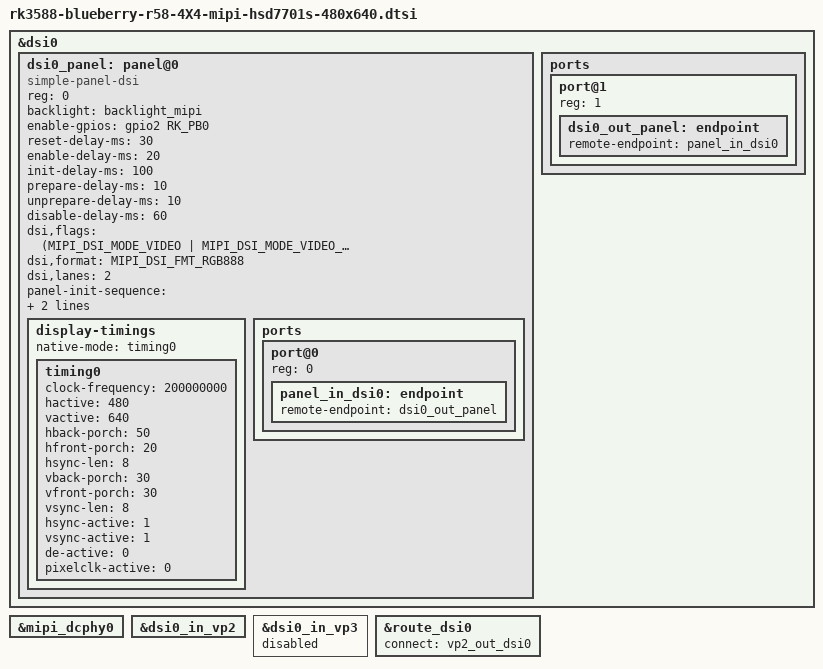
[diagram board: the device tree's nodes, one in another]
// SPDX-License-Identifier: (GPL-2.0+ OR MIT)
/*
 * Copyright (c) 2021 Rockchip Electronics Co., Ltd.
 *
 */

#include "dt-bindings/usb/pd.h"



&dsi0 {
	status = "okay";
	//rockchip,lane-rate = <1000>;
	dsi0_panel: panel@0 {
		status = "okay";
		compatible = "simple-panel-dsi";
		reg = <0>;
		backlight = <&backlight_mipi>;
		//power-supply = <&vcc3v3_mipi_lcd_power>;
		//reset-gpios =  <&gpio3 RK_PC4 GPIO_ACTIVE_LOW>; 
		enable-gpios = <&gpio2 RK_PB0 GPIO_ACTIVE_HIGH>;
		reset-delay-ms = <30>;
		enable-delay-ms = <20>;
		init-delay-ms = <100>;
		prepare-delay-ms = <10>;
		unprepare-delay-ms = <10>;
		disable-delay-ms = <60>;
		dsi,flags = <(MIPI_DSI_MODE_VIDEO | MIPI_DSI_MODE_VIDEO_BURST |
			MIPI_DSI_MODE_LPM | MIPI_DSI_MODE_EOT_PACKET)>;
		dsi,format = <MIPI_DSI_FMT_RGB888>;
		dsi,lanes  = <2>;

		//gc9053v zhengsao
		/*panel-init-sequence = [
			29 00 06 F0 55 AA 52 08 00
			29 00 03 F6 5A 87

			23 00 02 C1 3F
			23 00 02 CD 25
			23 00 02 C9 10

			23 00 02 F8 8A
			23 00 02 AC 45
			23 00 02 A7 47
			23 00 02 A0 DD
			29 00 05 86 99 A3 A3 31
			29 00 05 FA 08 08 00 04
			23 00 02 A3 EE
			29 00 04 FD 28 3C 00

			23 00 02 9A 4A
			23 00 02 9B 22
			29 00 03 82 00 00
			23 00 02 80 64
			23 00 B1 10

			29 00 21 6D 1E 1E 1E 10 0F 0A 09 1E 01 1F 00 07 0D 03 1E 1E 1E 1E 06 0E 08 00 1F 02 1E 11 12 17 18 1E 1E 1E
			29 00 11 64 38 09 02 7F 03 03 38 07 02 81 03 03 7A 7A 7A 7A
			29 00 11 67 38 05 02 83 03 03 38 03 02 85 03 03 7A 7A 7A 7A
			29 00 11 66 72 A7 02 9B 03 03 72 A7 02 9B 03 03 7A 7A 7A 7A
			29 00 11 65 72 A7 02 9B 03 03 72 A7 02 9B 03 03 7A 7A 7A 7A
			29 00 09 60 38 0D 7A 7A 38 0C 7A 7A
			29 00 09 61 B2 9B 7A 7A B2 9C 7A 7A
			29 00 09 62 B2 9C 7A 7A B2 9B 7A 7A
			29 00 09 63 38 0B 7A 7A 38 0A 7A 7A

			23 00 02 6B 07
			29 00 03 7A 13 1A
			29 00 03 7B 13 1A
			29 00 08 69 14 22 14 22 14 22 08

			29 00 35 D1 00 00 00 11 00 5C 00 7F 00 A8 00 D0 00 EE 01 18 01 40 01 84 01 BC 02 14 02 8D 02 8F 02 C6 03 31 03 45 03 8F 03 90 03 C5 03 C8 03 DB 03 E7 03 F4 03 FB 03 FF
			29 00 35 D2 00 00 00 11 00 5C 00 7F 00 A8 00 D0 00 EE 01 18 01 40 01 84 01 BC 02 14 02 8D 02 8F 02 C6 03 31 03 45 03 8F 03 90 03 C5 03 C8 03 DB 03 E7 03 F4 03 FB 03 FF
			29 00 35 D3 00 00 00 11 00 5C 00 7F 00 A8 00 D0 00 EE 01 18 01 40 01 84 01 BC 02 14 02 8D 02 8F 02 C6 03 31 03 45 03 8F 03 90 03 C5 03 C8 03 DB 03 E7 03 F4 03 FB 03 FF
			29 00 35 D4 00 00 00 11 00 5C 00 7F 00 A8 00 D0 00 EE 01 18 01 40 01 84 01 BC 02 14 02 8D 02 8F 02 C6 03 31 03 45 03 8F 03 90 03 C5 03 C8 03 DB 03 E7 03 F4 03 FB 03 FF
			29 00 35 D5 00 00 00 11 00 5C 00 7F 00 A8 00 D0 00 EE 01 18 01 40 01 84 01 BC 02 14 02 8D 02 8F 02 C6 03 31 03 45 03 8F 03 90 03 C5 03 C8 03 DB 03 E7 03 F4 03 FB 03 FF
			29 00 35 D6 00 00 00 11 00 5C 00 7F 00 A8 00 D0 00 EE 01 18 01 40 01 84 01 BC 02 14 02 8D 02 8F 02 C6 03 31 03 45 03 8F 03 90 03 C5 03 C8 03 DB 03 E7 03 F4 03 FB 03 FF
			05 78 01 11		
			05 14 01 29
		];*/

		//gc9053v fansao
		panel-init-sequence = [
			29 00 06 F0 55 AA 52 08 00
			29 00 03 F6 5A 87

			23 00 02 C1 3F
			23 00 02 CD 25
			23 00 02 C9 10

			23 00 02 F8 8A
			23 00 02 AC 45
			23 00 02 A7 47
			23 00 02 A0 DD
			29 00 05 86 99 A3 A3 31
			29 00 05 FA 08 08 00 04
			23 00 02 A3 EE
			29 00 04 FD 28 3C 00

			23 00 02 9A 4A
			23 00 02 9B 22
			29 00 03 82 00 00
			23 00 02 80 64
			23 00 B1 13

			29 00 21 6D 1E 1E 1E 11 12 17 18 1E 01 1F 00 07 0D 03 1E 1E 1E 1E 06 0E 08 00 1F 02 1E 11 12 17 18 1E 1E 1E
			29 00 11 64 38 09 02 7F 03 03 38 07 02 81 03 03 7A 7A 7A 7A
			29 00 11 67 38 05 02 83 03 03 38 03 02 85 03 03 7A 7A 7A 7A
			29 00 11 65 72 A7 02 9B 03 03 72 A7 02 9B 03 03 7A 7A 7A 7A
			29 00 11 66 72 A7 02 9B 03 03 72 A7 02 9B 03 03 7A 7A 7A 7A
			29 00 09 60 38 0D 7A 7A 38 0C 7A 7A
			29 00 09 61 B2 9B 7A 7A B2 9C 7A 7A
			29 00 09 62 B2 9C 7A 7A B2 9B 7A 7A
			29 00 09 63 38 0B 7A 7A 38 0A 7A 7A

			23 00 02 6B 07
			29 00 03 7A 13 1A
			29 00 03 7B 13 1A
			29 00 08 69 14 22 14 22 14 22 08

			29 00 35 D1 00 00 00 11 00 5C 00 7F 00 A8 00 D0 00 EE 01 18 01 40 01 84 01 BC 02 14 02 8D 02 8F 02 C6 03 31 03 45 03 8F 03 90 03 C5 03 C8 03 DB 03 E7 03 F4 03 FB 03 FF
			29 00 35 D2 00 00 00 11 00 5C 00 7F 00 A8 00 D0 00 EE 01 18 01 40 01 84 01 BC 02 14 02 8D 02 8F 02 C6 03 31 03 45 03 8F 03 90 03 C5 03 C8 03 DB 03 E7 03 F4 03 FB 03 FF
			29 00 35 D3 00 00 00 11 00 5C 00 7F 00 A8 00 D0 00 EE 01 18 01 40 01 84 01 BC 02 14 02 8D 02 8F 02 C6 03 31 03 45 03 8F 03 90 03 C5 03 C8 03 DB 03 E7 03 F4 03 FB 03 FF
			29 00 35 D4 00 00 00 11 00 5C 00 7F 00 A8 00 D0 00 EE 01 18 01 40 01 84 01 BC 02 14 02 8D 02 8F 02 C6 03 31 03 45 03 8F 03 90 03 C5 03 C8 03 DB 03 E7 03 F4 03 FB 03 FF
			29 00 35 D5 00 00 00 11 00 5C 00 7F 00 A8 00 D0 00 EE 01 18 01 40 01 84 01 BC 02 14 02 8D 02 8F 02 C6 03 31 03 45 03 8F 03 90 03 C5 03 C8 03 DB 03 E7 03 F4 03 FB 03 FF
			29 00 35 D6 00 00 00 11 00 5C 00 7F 00 A8 00 D0 00 EE 01 18 01 40 01 84 01 BC 02 14 02 8D 02 8F 02 C6 03 31 03 45 03 8F 03 90 03 C5 03 C8 03 DB 03 E7 03 F4 03 FB 03 FF
			05 78 01 11		
			05 14 01 29
		];
/*
		panel-init-sequence = [
			29 00 06 F0 55 AA 52 08 00
			29 00 03 F6 5A 87

			23 00 02 C1 3F
			23 00 02 C2 0E
			23 00 02 C6 F8
			23 00 02 C9 10
			23 00 02 CD 25
			23 00 02 C9 10

			23 00 02 F8 8A
			23 00 02 AC 45
			23 00 02 A7 47
			23 00 02 A0 DD
			29 00 05 86 99 A3 A3 31
			29 00 05 FA 08 08 00 04
			23 00 02 A3 EE
			29 00 04 FD 28 3C 00

			23 00 02 71 48
			23 00 02 72 48
			29 00 03 73 00 44
			23 00 02 97 EE
			23 00 02 83 93
			23 00 02 9A 84
			23 00 02 9B 49
			29 00 03 82 3A 3A
			23 00 B1 10

			29 00 03 7A 13 1A
			29 00 03 7B 13 1A

			29 00 08 69 14 22 14 22 44 22 08

			//29 00 21 6D 1E 1E 13 14 11 12 1E 0D 02 08 03 04 00 1F 1E 1E 1E 1E 1F 00 04 03 07 01 0D 1E 0A 09 0C 0B 1E 1E
			29 00 21 1E 00 09 0F 01 1F 1E 1E 1E 1E 1E 1E 1E 1E 1E 1E 1E 1E 1E 1E 1E 1E 1E 1E 1E 1E 1E 1F 08 10 0A 00 1E
			29 00 09 60 18 08 7A 7A 18 02 7A 7A
			29 00 09 63 18 02 7A 7A 18 02 7A 7A

			29 00 11 64 18 07 03 21 03 03 18 06 03 22 03 03 7A 7A 7A 7A
			29 00 11 65 18 05 03 23 03 03 18 04 03 24 03 03 7A 7A 7A 7A

			29 00 08 69 04 22 14 22 44 22 08

			29 00 35 D1 00 00 00 3D 00 72 00 97 00 B1 00 E1 01 03 01 3D 01 6C 01 B7 01 F1 02 4F 02 98 02 99 02 DB 03 25 03 51 03 8D 03 AA 03 C3 03 D1 03 E4 03 EE 03 F9 03 FC 03 FF
			29 00 35 D2 00 00 00 3D 00 72 00 97 00 B1 00 E1 01 03 01 3D 01 6C 01 B7 01 F1 02 4F 02 98 02 99 02 DB 03 25 03 51 03 8D 03 AA 03 C3 03 D1 03 E4 03 EE 03 F9 03 FC 03 FF
			29 00 35 D3 00 00 00 3D 00 72 00 97 00 B1 00 E1 01 03 01 3D 01 6C 01 B7 01 F1 02 4F 02 98 02 99 02 DB 03 25 03 51 03 8D 03 AA 03 C3 03 D1 03 E4 03 EE 03 F9 03 FC 03 FF
			29 00 35 D4 00 00 00 3D 00 72 00 97 00 B1 00 E1 01 03 01 3D 01 6C 01 B7 01 F1 02 4F 02 98 02 99 02 DB 03 25 03 51 03 8D 03 AA 03 C3 03 D1 03 E4 03 EE 03 F9 03 FC 03 FF
			29 00 35 D5 00 00 00 3D 00 72 00 97 00 B1 00 E1 01 03 01 3D 01 6C 01 B7 01 F1 02 4F 02 98 02 99 02 DB 03 25 03 51 03 8D 03 AA 03 C3 03 D1 03 E4 03 EE 03 F9 03 FC 03 FF
			29 00 35 D6 00 00 00 3D 00 72 00 97 00 B1 00 E1 01 03 01 3D 01 6C 01 B7 01 F1 02 4F 02 98 02 99 02 DB 03 25 03 51 03 8D 03 AA 03 C3 03 D1 03 E4 03 EE 03 F9 03 FC 03 FF
			05 78 01 11		
			05 14 01 29
		];
*/
		//网上
		/*panel-init-sequence = [
			39 00 06 F0 55 AA 52 08 00
			39 00 03 F6 5A 87
			23 00 02 C1 3F
			23 00 02 CD 25
			23 00 02 C9 10
			23 00 02 F8 8A
			23 00 02 AC 45
			23 00 02 A7 47
			23 00 02 A0 EE
			39 00 05 86 99 A3 A3 41
			39 00 05 FA 8F 00 00 04
			23 00 02 A3 6E
			39 00 04 FD 28 3C 00
			23 00 02 B1 10
			39 00 03 7A 0F 13
			39 00 03 7B 0F 13
			39 00 21 6D 07 1E 01 00 1F 09 0A 0C 0E 1E 1E 1E 1E 1E 1E 1E 1E 1E 1E 1E 1E 1E 1E 0F 0D 0B 10 1F 00 02 1E 08
			39 00 11 64 18 03 03 F3 03 03 18 01 03 F5 03 03 6D 6D 6D 6D
			39 00 11 65 10 00 03 F6 03 03 10 01 03 F7 03 03 6D 6D 6D 6D
			39 00 11 66 10 02 03 F8 03 03 10 03 03 F9 03 03 6D 6D 6D 6D
			39 00 11 67 10 04 03 FA 03 03 18 02 03 F4 03 03 6D 6D 6D 6D
			39 00 09 60 18 07 6D 6D 18 06 6D 6D
			39 00 09 63 13 F1 6D 6D 13 F2 6D 6D
			39 00 08 69 14 22 14 22 44 22 08
			23 00 02 6B 07
			39 00 35 D1 00 00 00 10 00 2f 00 48 00 62 00 80 00 A8 00 Fa 01 48 01 97 01 C8 02 0f 02 47 02 49 02 78 02 a7 02 c0 02 e2 02 f3 03 0c 03 1f 03 36 03 44 03 55 03 80 03 FF
			39 00 35 D2 00 00 00 10 00 2f 00 48 00 62 00 80 00 A8 00 Fa 01 48 01 97 01 C8 02 0f 02 47 02 49 02 78 02 a7 02 c0 02 e2 02 f3 03 0c 03 1f 03 36 03 44 03 55 03 80 03 FF
			39 00 35 D3 00 00 00 10 00 2f 00 48 00 62 00 80 00 A8 00 Fa 01 48 01 97 01 C8 02 0f 02 47 02 49 02 78 02 a7 02 c0 02 e2 02 f3 03 0c 03 1f 03 36 03 44 03 55 03 80 03 FF
			39 00 35 D4 00 00 00 10 00 2f 00 48 00 62 00 80 00 A8 00 Fa 01 48 01 97 01 C8 02 0f 02 47 02 49 02 78 02 a7 02 c0 02 e2 02 f3 03 0c 03 1f 03 36 03 44 03 55 03 80 03 FF
			39 00 35 D5 00 00 00 10 00 2f 00 48 00 62 00 80 00 A8 00 Fa 01 48 01 97 01 C8 02 0f 02 47 02 49 02 78 02 a7 02 c0 02 e2 02 f3 03 0c 03 1f 03 36 03 44 03 55 03 80 03 FF
			39 00 35 D6 00 00 00 10 00 2f 00 48 00 62 00 80 00 A8 00 Fa 01 48 01 97 01 C8 02 0f 02 47 02 49 02 78 02 a7 02 c0 02 e2 02 f3 03 0c 03 1f 03 36 03 44 03 55 03 80 03 FF
			23 78 02 11 00
			23 14 02 29 00

		];*/

		/* //换39
		panel-init-sequence = [
			39 00 06 F0 55 AA 52 08 00
			39 00 03 F6 5A 87
			39 00 02 C1 3F
			39 00 02 C6 F8
			39 00 02 C9 10
			39 00 02 CD 25
			39 00 02 F8 8A
			39 00 02 AC 45
			39 00 02 A7 47
			39 00 02 A0 99
			39 00 05 86 99 A3 A3 41
			39 00 05 FA 08 08 00 04
			39 00 02 A3 22
			39 00 04 FD 3C 3C 00
			39 00 02 6B 07
			39 00 02 9A 75
			39 00 02 9B 85
			39 00 03 82 40 40
			39 00 02 B1 13
			39 00 03 7A 13 1A
			39 00 03 7B 13 1A
			39 00 08 69 14 22 14 22 44 22 08
			39 00 21 6D 1E 1E 0F 10 09 0A 1E 0D 02 08 03 04 00 1F 1E 1E 1E 1E 1F 00 04 03 07 01 0D 1E 17 18 11 12 1E 1E
			39 00 09 60 38 0A 21 6C 38 09 21 6C
			39 00 09 63 38 08 21 6C 38 07 21 6C
			39 00 09 62 82 91 6C 6C 32 83 21 6C
			39 00 09 61 32 83 21 6C 82 91 6C 6C
			39 00 07 66 78 0E 02 91 03 03
			39 00 11 66 78 0E 02 91 03 03 38 06 02 81 03 03 21 6C 21 6C
			39 00 11 64 38 08 02 7E 03 03 38 06 02 81 03 03 21 6C 21 6C
			39 00 11 65 38 04 02 83 03 03 78 0E 02 91 03 03 21 6C 21 6C
			39 00 11 67 38 04 02 83 03 03 38 02 02 85 03 03 21 6C 21 6C
			39 00 35 D1 00 00 00 00 00 00 00 5D 00 60 00 B0 00 B3 00 EE 01 1D 01 6D 01 A6 02 0B 02 55 02 56 02 9D 02 E4 03 10 03 44 03 84 03 90 03 AE 03 B5 03 D8 03 E6 03 F7 03 FF
			39 00 35 D2 00 00 00 00 00 00 00 5D 00 60 00 B0 00 B3 00 EE 01 1D 01 6D 01 A6 02 0B 02 55 02 56 02 9D 02 E4 03 10 03 44 03 84 03 90 03 AE 03 B5 03 D8 03 E6 03 E7 03 FF
			39 00 35 D3 00 00 00 00 00 00 00 5D 00 60 00 B0 00 B3 00 EE 01 1D 01 6D 01 A6 02 0B 02 55 02 56 02 9D 02 E4 03 10 03 44 03 84 03 90 03 AE 03 B5 03 D8 03 E6 03 F7 03 FF
			39 00 35 D4 00 00 00 00 00 00 00 5D 00 60 00 B0 00 B3 00 EE 01 1D 01 6D 01 A6 02 0B 02 55 02 56 02 9D 02 E4 03 10 03 44 03 84 03 90 03 AE 03 B5 03 D8 03 E6 03 F7 03 FF
			39 00 35 D5 00 00 00 00 00 00 00 5D 00 60 00 B0 00 B3 00 EE 01 1D 01 6D 01 A6 02 0B 02 55 02 56 02 9D 02 E4 03 10 03 44 03 84 03 90 03 AE 03 B5 03 D8 03 E6 03 F7 03 FF
			39 00 35 D6 00 00 00 00 00 00 00 5D 00 60 00 B0 00 B3 00 EE 01 1D 01 6D 01 A6 02 0B 02 55 02 56 02 9D 02 E4 03 10 03 44 03 84 03 90 03 AE 03 B5 03 D8 03 E6 03 F7 03 FF
			15 78 01 11		
			15 14 01 29
		];*/

		/*
		panel-init-sequence = [
			29 00 06 F0 55 AA 52 08 00
			29 00 03 F6 5A 87
			23 00 02 C1 3F
			23 00 02 C6 F8
			23 00 02 C9 10
			23 00 02 CD 25
			23 00 02 F8 8A
			23 00 02 AC 45
			23 00 02 A7 47
			23 00 02 A0 99
			29 00 05 86 99 A3 A3 41
			29 00 05 FA 08 08 00 04
			23 00 02 A3 22
			29 00 04 FD 3C 3C 00
			23 00 02 6B 07
			23 00 02 9A 75
			23 00 02 9B 85
			29 00 03 82 40 40
			23 00 02 B1 13
			29 00 03 7A 13 1A
			29 00 03 7B 13 1A
			29 00 08 69 14 22 14 22 44 22 08
			29 00 21 6D 1E 1E 0F 10 09 0A 1E 0D 02 08 03 04 00 1F 1E 1E 1E 1E 1F 00 04 03 07 01 0D 1E 17 18 11 12 1E 1E
			29 00 09 60 38 0A 21 6C 38 09 21 6C
			29 00 09 63 38 08 21 6C 38 07 21 6C
			29 00 09 62 82 91 6C 6C 32 83 21 6C
			29 00 09 61 32 83 21 6C 82 91 6C 6C
			29 00 07 66 78 0E 02 91 03 03
			29 00 11 66 78 0E 02 91 03 03 38 06 02 81 03 03 21 6C 21 6C
			29 00 11 64 38 08 02 7E 03 03 38 06 02 81 03 03 21 6C 21 6C
			29 00 11 65 38 04 02 83 03 03 78 0E 02 91 03 03 21 6C 21 6C
			29 00 11 67 38 04 02 83 03 03 38 02 02 85 03 03 21 6C 21 6C
			29 00 35 D1 00 00 00 00 00 00 00 5D 00 60 00 B0 00 B3 00 EE 01 1D 01 6D 01 A6 02 0B 02 55 02 56 02 9D 02 E4 03 10 03 44 03 84 03 90 03 AE 03 B5 03 D8 03 E6 03 F7 03 FF
			29 00 35 D2 00 00 00 00 00 00 00 5D 00 60 00 B0 00 B3 00 EE 01 1D 01 6D 01 A6 02 0B 02 55 02 56 02 9D 02 E4 03 10 03 44 03 84 03 90 03 AE 03 B5 03 D8 03 E6 03 E7 03 FF
			29 00 35 D3 00 00 00 00 00 00 00 5D 00 60 00 B0 00 B3 00 EE 01 1D 01 6D 01 A6 02 0B 02 55 02 56 02 9D 02 E4 03 10 03 44 03 84 03 90 03 AE 03 B5 03 D8 03 E6 03 F7 03 FF
			29 00 35 D4 00 00 00 00 00 00 00 5D 00 60 00 B0 00 B3 00 EE 01 1D 01 6D 01 A6 02 0B 02 55 02 56 02 9D 02 E4 03 10 03 44 03 84 03 90 03 AE 03 B5 03 D8 03 E6 03 F7 03 FF
			29 00 35 D5 00 00 00 00 00 00 00 5D 00 60 00 B0 00 B3 00 EE 01 1D 01 6D 01 A6 02 0B 02 55 02 56 02 9D 02 E4 03 10 03 44 03 84 03 90 03 AE 03 B5 03 D8 03 E6 03 F7 03 FF
			29 00 35 D6 00 00 00 00 00 00 00 5D 00 60 00 B0 00 B3 00 EE 01 1D 01 6D 01 A6 02 0B 02 55 02 56 02 9D 02 E4 03 10 03 44 03 84 03 90 03 AE 03 B5 03 D8 03 E6 03 F7 03 FF
			05 78 01 11		
			05 14 01 29
		];*/
/*
		panel-init-sequence = [
			29 00 06 F0 55 AA 52 08 00
			29 00 03 F6 5A 87

			23 00 02 C1 3F
			23 00 02 C6 F8
			23 00 02 C9 10
			23 00 02 CD 25

			23 00 02 3A 50
			23 00 02 F8 8A
			23 00 02 AC 45
			23 00 02 A7 47
			23 00 02 A0 99
			29 00 05 86 99 A3 A3 41
			29 00 05 FA 08 08 00 04
			23 00 02 A3 22
			29 00 04 FD 3C 3C 00

			23 00 02 6B 07
			23 00 02 9A 75
			23 00 02 9B 85
			29 00 03 82 40 40
			23 00 02 B1 10

			29 00 03 7A 13 1A
			29 00 03 7B 13 1A

			29 00 08 69 14 22 14 22 44 22 08

			29 00 21 6D 1E 1E 13 14 11 12 1E 0D 02 08 03 04 00 1F 1E 1E 1E 1E 1F 00 04 03 07 01 0D 1E 0A 09 0C 0B 1E 1E
			29 00 09 60 38 0A 21 6C 38 09 21 6C
			29 00 09 63 38 08 21 6C 38 07 21 6C
			29 00 09 61 32 83 21 6C 82 91 6C 6C
			29 00 07 66 78 0E 02 91 03 03

			29 00 11 64 38 08 02 7E 03 03 38 06 02 81 03 03 21 6C 21 6C
			29 00 11 65 38 04 02 83 03 03 38 02 02 85 03 03 21 6C 21 6C

			29 00 35 D1 00 00 00 00 00 00 00 5D 00 60 00 B0 00 B3 00 EE 01 1D 01 6D 01 A6 02 0B 02 55 02 56 02 9D 02 E4 03 10 03 44 03 84 03 90 03 AE 03 B5 03 D8 03 E6 03 F7 03 FF
			29 00 35 D2 00 00 00 00 00 00 00 5D 00 60 00 B0 00 B3 00 EE 01 1D 01 6D 01 A6 02 0B 02 55 02 56 02 9D 02 E4 03 10 03 44 03 84 03 90 03 AE 03 B5 03 D8 03 E6 03 E7 03 FF
			29 00 35 D3 00 00 00 00 00 00 00 5D 00 60 00 B0 00 B3 00 EE 01 1D 01 6D 01 A6 02 0B 02 55 02 56 02 9D 02 E4 03 10 03 44 03 84 03 90 03 AE 03 B5 03 D8 03 E6 03 F7 03 FF
			29 00 35 D4 00 00 00 00 00 00 00 5D 00 60 00 B0 00 B3 00 EE 01 1D 01 6D 01 A6 02 0B 02 55 02 56 02 9D 02 E4 03 10 03 44 03 84 03 90 03 AE 03 B5 03 D8 03 E6 03 F7 03 FF
			29 00 35 D5 00 00 00 00 00 00 00 5D 00 60 00 B0 00 B3 00 EE 01 1D 01 6D 01 A6 02 0B 02 55 02 56 02 9D 02 E4 03 10 03 44 03 84 03 90 03 AE 03 B5 03 D8 03 E6 03 F7 03 FF
			29 00 35 D6 00 00 00 00 00 00 00 5D 00 60 00 B0 00 B3 00 EE 01 1D 01 6D 01 A6 02 0B 02 55 02 56 02 9D 02 E4 03 10 03 44 03 84 03 90 03 AE 03 B5 03 D8 03 E6 03 F7 03 FF
			05 78 01 11		
			05 14 01 29
		];*/
		/*
		panel-init-sequence = [
			05 78 01 11			
			05 14 01 29
		];*/
		panel-exit-sequence = [
		];

		display-timings {
			native-mode = <&timing0>;

			timing0: timing0 {
				clock-frequency = <200000000>;  //159391260  159747840
				hactive = <480>;
				vactive = <640>; 
				hback-porch = <50>;
				hfront-porch = <20>;
				hsync-len = <8>;
				vback-porch = <30>;
				vfront-porch = <30>;
				vsync-len = <8>;
				hsync-active = <1>;
				vsync-active = <1>;
				de-active = <0>;
				pixelclk-active = <0>;
				};

			/*
			timing0: timing0 {
				clock-frequency = <200000000>;  //159391260  159747840
				hactive = <480>;
				vactive = <640>; 
				hback-porch = <20>;
				hfront-porch = <32>;
				hsync-len = <16>;
				vback-porch = <20>;
				vfront-porch = <12>;
				vsync-len = <8>;
				hsync-active = <1>;
				vsync-active = <1>;
				de-active = <0>;
				pixelclk-active = <0>;
				};*/
		};

		ports {
			#address-cells = <1>;
			#size-cells = <0>;

			port@0 {
				reg = <0>;
				panel_in_dsi0: endpoint {
					remote-endpoint = <&dsi0_out_panel>;
				};
			};
		};
	};

		ports {
			#address-cells = <1>;
			#size-cells = <0>;

			port@1 {
				reg = <1>;
				dsi0_out_panel: endpoint {
					remote-endpoint = <&panel_in_dsi0>;
				};
			};
		};
	
};

&dsi0 {
	status = "okay";
};

&mipi_dcphy0 {
	status = "okay";
};

&dsi0_in_vp2 {
	status = "okay";
};

&dsi0_in_vp3 {
	status = "disabled";
};

&route_dsi0 {
	status = "okay";
	connect = <&vp2_out_dsi0>;
};
